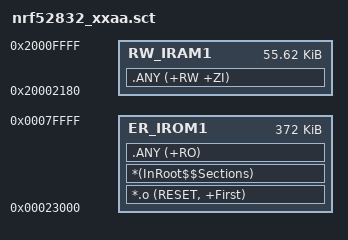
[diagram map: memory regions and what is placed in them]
; *************************************************************
; *** Scatter-Loading Description File generated by uVision ***
; *************************************************************

LR_IROM1 0x00023000 0x0005D000  {    ; load region size_region
  ER_IROM1 0x00023000 0x0005D000  {  ; load address = execution address
   *.o (RESET, +First)
   *(InRoot$$Sections)
   .ANY (+RO)
  }
  RW_IRAM1 0x20002180 0x0000DE80  {  ; RW data
   .ANY (+RW +ZI)
  }
}

